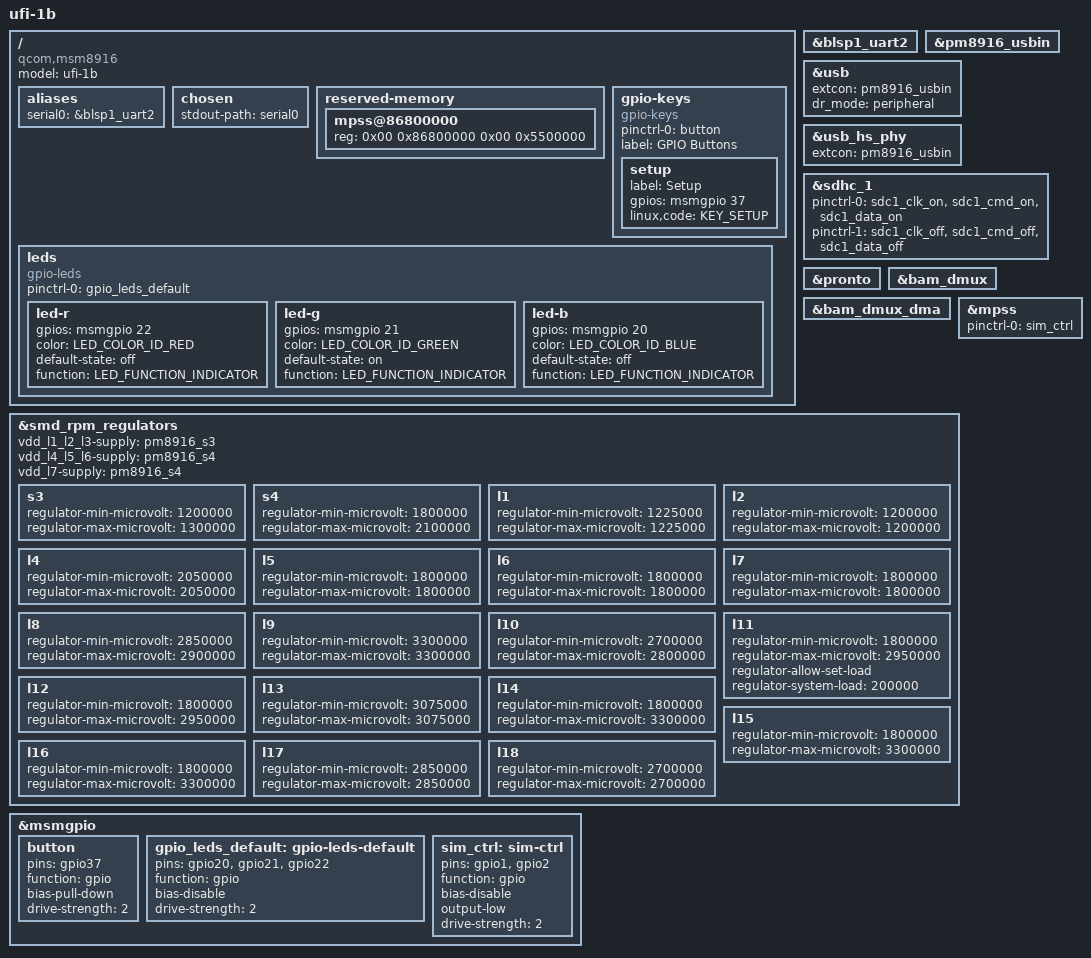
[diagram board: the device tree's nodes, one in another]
// SPDX-License-Identifier: GPL-2.0-only

/dts-v1/;

#include "msm8916-pm8916.dtsi"
#include <dt-bindings/gpio/gpio.h>
#include <dt-bindings/leds/common.h>

/ {
	model = "ufi-1b";
	compatible = "qcom,msm8916";

	aliases {
		serial0 = &blsp1_uart2;
	};

	chosen {
		stdout-path = "serial0";
	};

	reserved-memory {
		mpss@86800000 {
				reg = <0x00 0x86800000 0x00 0x5500000>;
		};
	};

	gpio-keys {
		compatible = "gpio-keys";

		pinctrl-names = "default";
		pinctrl-0 = <&button>;

		label = "GPIO Buttons";

		setup {
			label = "Setup";
			gpios = <&msmgpio 37 GPIO_ACTIVE_HIGH>;
			linux,code = <KEY_SETUP>;
		};
	};

	leds {
		compatible = "gpio-leds";

		pinctrl-names = "default";
		pinctrl-0 = <&gpio_leds_default>;

		led-r {
			gpios = <&msmgpio 22 GPIO_ACTIVE_HIGH>;
			color = <LED_COLOR_ID_RED>;
			default-state = "off";
			function = LED_FUNCTION_INDICATOR;
		};

		led-g {
			gpios = <&msmgpio 21 GPIO_ACTIVE_HIGH>;
			color = <LED_COLOR_ID_GREEN>;
			default-state = "on";
			function = LED_FUNCTION_INDICATOR;
		};

		led-b {
			gpios = <&msmgpio 20 GPIO_ACTIVE_HIGH>;
			color = <LED_COLOR_ID_BLUE>;
			default-state = "off";
			function = LED_FUNCTION_INDICATOR;
		};
	};
};

&blsp1_uart2 {
	status = "okay";
};

&pm8916_usbin {
	status = "okay";
};

&usb {
	status = "okay";
	extcon = <&pm8916_usbin>;
	dr_mode = "peripheral";
};

&usb_hs_phy {
	extcon = <&pm8916_usbin>;
};

&sdhc_1 {
	status = "okay";

	pinctrl-names = "default", "sleep";
	pinctrl-0 = <&sdc1_clk_on &sdc1_cmd_on &sdc1_data_on>;
	pinctrl-1 = <&sdc1_clk_off &sdc1_cmd_off &sdc1_data_off>;
};

&pronto {
	status = "okay";
};

&bam_dmux {
	status = "okay";
};

&bam_dmux_dma {
	status = "okay";
};

&mpss {
	status = "okay";

	pinctrl-names = "default";
	pinctrl-0 = <&sim_ctrl>;
};

&smd_rpm_regulators {
	vdd_l1_l2_l3-supply = <&pm8916_s3>;
	vdd_l4_l5_l6-supply = <&pm8916_s4>;
	vdd_l7-supply = <&pm8916_s4>;

	s3 {
		regulator-min-microvolt = <1200000>;
		regulator-max-microvolt = <1300000>;
	};

	s4 {
		regulator-min-microvolt = <1800000>;
		regulator-max-microvolt = <2100000>;
	};

	l1 {
		regulator-min-microvolt = <1225000>;
		regulator-max-microvolt = <1225000>;
	};

	l2 {
		regulator-min-microvolt = <1200000>;
		regulator-max-microvolt = <1200000>;
	};

	l4 {
		regulator-min-microvolt = <2050000>;
		regulator-max-microvolt = <2050000>;
	};

	l5 {
		regulator-min-microvolt = <1800000>;
		regulator-max-microvolt = <1800000>;
	};

	l6 {
		regulator-min-microvolt = <1800000>;
		regulator-max-microvolt = <1800000>;
	};

	l7 {
		regulator-min-microvolt = <1800000>;
		regulator-max-microvolt = <1800000>;
	};

	l8 {
		regulator-min-microvolt = <2850000>;
		regulator-max-microvolt = <2900000>;
	};

	l9 {
		regulator-min-microvolt = <3300000>;
		regulator-max-microvolt = <3300000>;
	};

	l10 {
		regulator-min-microvolt = <2700000>;
		regulator-max-microvolt = <2800000>;
	};

	l11 {
		regulator-min-microvolt = <1800000>;
		regulator-max-microvolt = <2950000>;
		regulator-allow-set-load;
		regulator-system-load = <200000>;
	};

	l12 {
		regulator-min-microvolt = <1800000>;
		regulator-max-microvolt = <2950000>;
	};

	l13 {
		regulator-min-microvolt = <3075000>;
		regulator-max-microvolt = <3075000>;
	};

	l14 {
		regulator-min-microvolt = <1800000>;
		regulator-max-microvolt = <3300000>;
	};

	l15 {
		regulator-min-microvolt = <1800000>;
		regulator-max-microvolt = <3300000>;
	};

	l16 {
		regulator-min-microvolt = <1800000>;
		regulator-max-microvolt = <3300000>;
	};

	l17 {
		regulator-min-microvolt = <2850000>;
		regulator-max-microvolt = <2850000>;
	};

	l18 {
		regulator-min-microvolt = <2700000>;
		regulator-max-microvolt = <2700000>;
	};
};

&msmgpio {
	button: button {
		pins = "gpio37";
		function = "gpio";

		bias-pull-down;
		drive-strength = <2>;
	};

	gpio_leds_default: gpio-leds-default {
		pins = "gpio20", "gpio21", "gpio22";
		function = "gpio";

		bias-disable;
		drive-strength = <2>;
	};

	sim_ctrl: sim-ctrl {
		pins = "gpio1", "gpio2";
		function = "gpio";

		bias-disable;
		output-low;
		drive-strength = <2>;
	};
};
